# STM32WB55 register map
File version: 2.0
CPU: CM4 r0p1, little endian, MPU, FPU, 4 interrupt priority bits
Registers are 32-bit, read-write, reset 0x0 unless marked. A register's access mark holds for its fields unless they carry their own. Offsets are from the block's base; [hi:lo] are bit positions; {n}, {i} and the like mark numbered series.

## GPIOA — General-purpose I/Os
Base 0x48000000
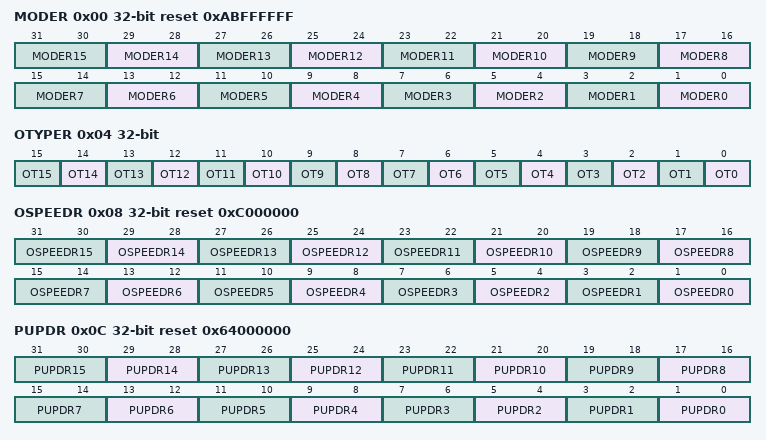
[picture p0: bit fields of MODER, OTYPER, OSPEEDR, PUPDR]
0x00 MODER reset 0xABFFFFFF — GPIO port mode register
  [2n+1:2n] MODER{n} (n=0..15) — Port x configuration pin {n}
    0=Input mode (reset state); 1=Output (General purpose output mode); 2=Alternate function mode; 3=Analog mode
0x04 OTYPER — GPIO port output type register
  [n] OT{n} (n=0..15) — Port x configuration pin {n}
    0=PushPull (Output push-pull (reset state)); 1=OpenDrain (Output open-drain)
0x08 OSPEEDR reset 0xC000000 — GPIO port output speed register
  [2n+1:2n] OSPEEDR{n} (n=0..15) — Port x configuration pin {n}
    0=LowSpeed; 1=MediumSpeed; 2=HighSpeed; 3=VeryHighSpeed
0x0C PUPDR reset 0x64000000 — GPIO port pull-up/pull-down register
  [2n+1:2n] PUPDR{n} (n=0..15) — Port x configuration pin {n}
    0=Floating (No pull-up, pull-down); 1=PullUp; 2=PullDown
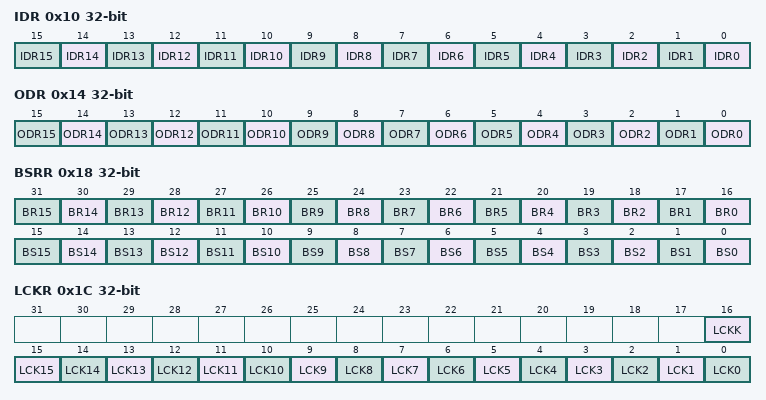
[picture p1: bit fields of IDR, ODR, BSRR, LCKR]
0x10 IDR ro — GPIO port input data register
  [n] IDR{n} (n=0..15) — Port input data pin {n}
    0=Low (Input is logic low); 1=High (Input is logic high)
0x14 ODR — GPIO port output data register
  [n] ODR{n} (n=0..15) — Port output data pin {n}
    0=Low (Set output to logic low); 1=High (Set output to logic high)
0x18 BSRR wo — GPIO port bit set/reset register
  [n+16] BR{n} (n=0..15) — Port x reset pin {n}
    1=Resets the corresponding ODRx bit
  [n] BS{n} (n=0..15) — Port x set pin {n}
    1=Set (Sets the corresponding ODRx bit)
0x1C LCKR — GPIO port configuration lock register
  [16] LCKK — Port x lock bit y (y= 0..15)
    0=NotActive (Port configuration lock key not active); 1=Active (Port configuration lock key active)
  [n] LCK{n} (n=0..15) — Port x lock pin {n}
    0=Unlocked (Port configuration not locked); 1=Locked (Port configuration locked)
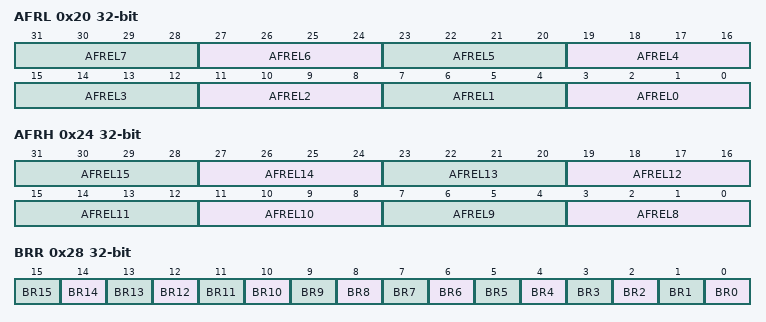
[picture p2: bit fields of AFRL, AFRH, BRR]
0x20 AFRL — GPIO alternate function low register
  [3:0] AFR{x} (x=EL0,EL1,EL2,EL3,EL4,EL5,EL6,EL7; step 4) — Alternate function selection for port x bit y (y = 0..7)
0x24 AFRH — GPIO alternate function high register
  [3:0] AFR{x} (x=EL8,EL9,EL10,EL11,EL12,EL13,EL14,EL15; step 4) — Alternate function selection for port x bit y (y = 8..15)
0x28 BRR wo — port bit reset register
  [n] BR{n} (n=0..15) — Port x reset pin {n}
    0=No action on the corresponding ODx bit; 1=Reset the ODx bit

## GPIOB — General-purpose I/Os
Base 0x48000400
Registers as GPIOA; these are added or differ:
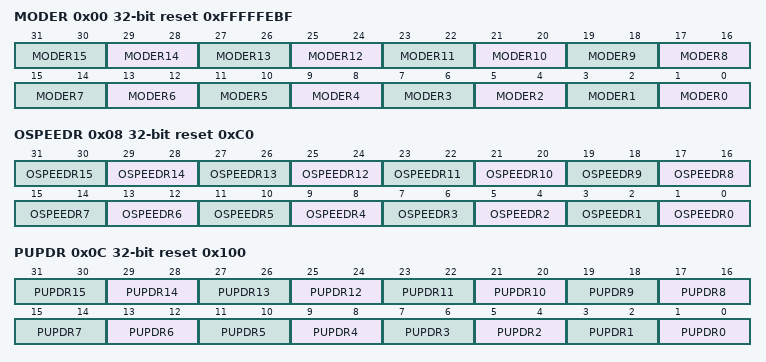
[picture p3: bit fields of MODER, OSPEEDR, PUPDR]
0x00 MODER reset 0xFFFFFEBF — GPIO port mode register
  [2n+1:2n] MODER{n} (n=0..15) — Port x configuration pin {n}
    0=Input mode (reset state); 1=Output (General purpose output mode); 2=Alternate function mode; 3=Analog mode
0x08 OSPEEDR reset 0xC0 — GPIO port output speed register
  [2n+1:2n] OSPEEDR{n} (n=0..15) — Port x configuration pin {n}
    0=LowSpeed; 1=MediumSpeed; 2=HighSpeed; 3=VeryHighSpeed
0x0C PUPDR reset 0x100 — GPIO port pull-up/pull-down register
  [2n+1:2n] PUPDR{n} (n=0..15) — Port x configuration pin {n}
    0=Floating (No pull-up, pull-down); 1=PullUp; 2=PullDown

## GPIOC — General-purpose I/Os
Base 0x48000800
Same registers: GPIOD 0x48000C00
Registers as GPIOB; these are added or differ:
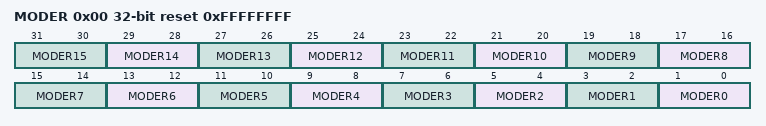
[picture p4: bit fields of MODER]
0x00 MODER reset 0xFFFFFFFF — GPIO port mode register
  [2n+1:2n] MODER{n} (n=0..15) — Port x configuration pin {n}
    0=Input mode (reset state); 1=Output (General purpose output mode); 2=Alternate function mode; 3=Analog mode

## GPIOE — General-purpose I/Os
Base 0x48001000
Registers as GPIOA; these are added or differ:
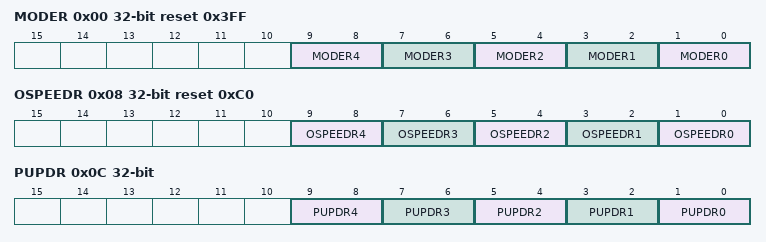
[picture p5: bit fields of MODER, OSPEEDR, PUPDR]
0x00 MODER reset 0x3FF — GPIO port mode register
  [2n+1:2n] MODER{n} (n=0..4) — Port x configuration pin {n}
    0=Input mode (reset state); 1=Output (General purpose output mode); 2=Alternate function mode; 3=Analog mode
0x08 OSPEEDR reset 0xC0 — GPIO port output speed register
  [2n+1:2n] OSPEEDR{n} (n=0..4) — Port x configuration pin {n}
    0=LowSpeed; 1=MediumSpeed; 2=HighSpeed; 3=VeryHighSpeed
0x0C PUPDR — GPIO port pull-up/pull-down register
  [2n+1:2n] PUPDR{n} (n=0..4) — Port x configuration pin {n}
    0=Floating (No pull-up, pull-down); 1=PullUp; 2=PullDown
